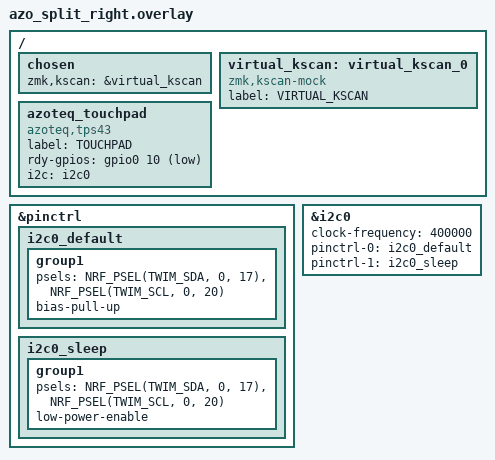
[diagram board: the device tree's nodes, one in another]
#include <dt-bindings/zmk/matrix_transform.h>
#include <dt-bindings/pinctrl/nrf-pinctrl.h>

&pinctrl {
    i2c0_default: i2c0_default {
        group1 {
            psels = <NRF_PSEL(TWIM_SDA, 0, 17)>,
                    <NRF_PSEL(TWIM_SCL, 0, 20)>;
            bias-pull-up;
        };
    };

    i2c0_sleep: i2c0_sleep {
        group1 {
            psels = <NRF_PSEL(TWIM_SDA, 0, 17)>,
                    <NRF_PSEL(TWIM_SCL, 0, 20)>;
            low-power-enable;
        };
    };
};

/ {
    chosen {
        zmk,kscan = &virtual_kscan;
    };

    virtual_kscan: virtual_kscan_0 {
        compatible = "zmk,kscan-mock";
        label = "VIRTUAL_KSCAN";
    };

    azoteq_touchpad: azoteq_touchpad {
        compatible = "azoteq,tps43";
        label = "TOUCHPAD";

        rdy-gpios = <&gpio0 10 GPIO_ACTIVE_LOW>;
        i2c = <&i2c0>;
    };
};

&i2c0 {
    status = "okay";
    clock-frequency = <400000>;
    
    pinctrl-0 = <&i2c0_default>;
    pinctrl-1 = <&i2c0_sleep>;
    pinctrl-names = "default", "sleep";
}; 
